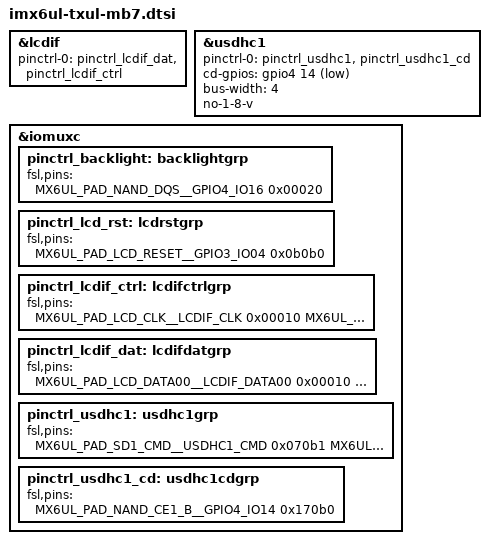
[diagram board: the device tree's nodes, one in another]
// SPDX-License-Identifier: GPL-2.0+
/*
 * Copyright (C) 2026 Ka-Ro Electronics GmbH
 * MB7 SD slot and LCD of TXUL.
 */

&lcdif {
	pinctrl-names = "default";
	pinctrl-0 = <&pinctrl_lcdif_dat &pinctrl_lcdif_ctrl>;
	status = "okay";
};

&usdhc1 {
	pinctrl-names = "default";
	pinctrl-0 = <&pinctrl_usdhc1 &pinctrl_usdhc1_cd>;
	cd-gpios = <&gpio4 14 GPIO_ACTIVE_LOW>;
	bus-width = <4>;
	no-1-8-v;
	status = "okay";
};

&iomuxc {
	pinctrl_backlight: backlightgrp {
		fsl,pins = <
			MX6UL_PAD_NAND_DQS__GPIO4_IO16		0x00020
		>;
	};

	pinctrl_lcd_rst: lcdrstgrp {
		fsl,pins = <
			MX6UL_PAD_LCD_RESET__GPIO3_IO04		0x0b0b0
		>;
	};

	pinctrl_lcdif_ctrl: lcdifctrlgrp {
		fsl,pins = <
			MX6UL_PAD_LCD_CLK__LCDIF_CLK		0x00010
			MX6UL_PAD_LCD_ENABLE__LCDIF_ENABLE	0x00010
			MX6UL_PAD_LCD_HSYNC__LCDIF_HSYNC	0x00010
			MX6UL_PAD_LCD_VSYNC__LCDIF_VSYNC	0x00010
		>;
	};

	pinctrl_lcdif_dat: lcdifdatgrp {
		fsl,pins = <
			MX6UL_PAD_LCD_DATA00__LCDIF_DATA00	0x00010
			MX6UL_PAD_LCD_DATA01__LCDIF_DATA01	0x00010
			MX6UL_PAD_LCD_DATA02__LCDIF_DATA02	0x00010
			MX6UL_PAD_LCD_DATA03__LCDIF_DATA03	0x00010
			MX6UL_PAD_LCD_DATA04__LCDIF_DATA04	0x00010
			MX6UL_PAD_LCD_DATA05__LCDIF_DATA05	0x00010
			MX6UL_PAD_LCD_DATA06__LCDIF_DATA06	0x00010
			MX6UL_PAD_LCD_DATA07__LCDIF_DATA07	0x00010
			MX6UL_PAD_LCD_DATA08__LCDIF_DATA08	0x00010
			MX6UL_PAD_LCD_DATA09__LCDIF_DATA09	0x00010
			MX6UL_PAD_LCD_DATA10__LCDIF_DATA10	0x00010
			MX6UL_PAD_LCD_DATA11__LCDIF_DATA11	0x00010
			MX6UL_PAD_LCD_DATA12__LCDIF_DATA12	0x00010
			MX6UL_PAD_LCD_DATA13__LCDIF_DATA13	0x00010
			MX6UL_PAD_LCD_DATA14__LCDIF_DATA14	0x00010
			MX6UL_PAD_LCD_DATA15__LCDIF_DATA15	0x00010
			MX6UL_PAD_LCD_DATA16__LCDIF_DATA16	0x00010
			MX6UL_PAD_LCD_DATA17__LCDIF_DATA17	0x00010
			MX6UL_PAD_LCD_DATA18__LCDIF_DATA18	0x00010
			MX6UL_PAD_LCD_DATA19__LCDIF_DATA19	0x00010
			MX6UL_PAD_LCD_DATA20__LCDIF_DATA20	0x00010
			MX6UL_PAD_LCD_DATA21__LCDIF_DATA21	0x00010
			MX6UL_PAD_LCD_DATA22__LCDIF_DATA22	0x00010
			MX6UL_PAD_LCD_DATA23__LCDIF_DATA23	0x00010
		>;
	};

	pinctrl_usdhc1: usdhc1grp {
		fsl,pins = <
			MX6UL_PAD_SD1_CMD__USDHC1_CMD		0x070b1
			MX6UL_PAD_SD1_CLK__USDHC1_CLK		0x07099
			MX6UL_PAD_SD1_DATA0__USDHC1_DATA0	0x070b1
			MX6UL_PAD_SD1_DATA1__USDHC1_DATA1	0x070b1
			MX6UL_PAD_SD1_DATA2__USDHC1_DATA2	0x070b1
			MX6UL_PAD_SD1_DATA3__USDHC1_DATA3	0x070b1
		>;
	};

	pinctrl_usdhc1_cd: usdhc1cdgrp {
		fsl,pins = <
			MX6UL_PAD_NAND_CE1_B__GPIO4_IO14	0x170b0
		>;
	};
};
